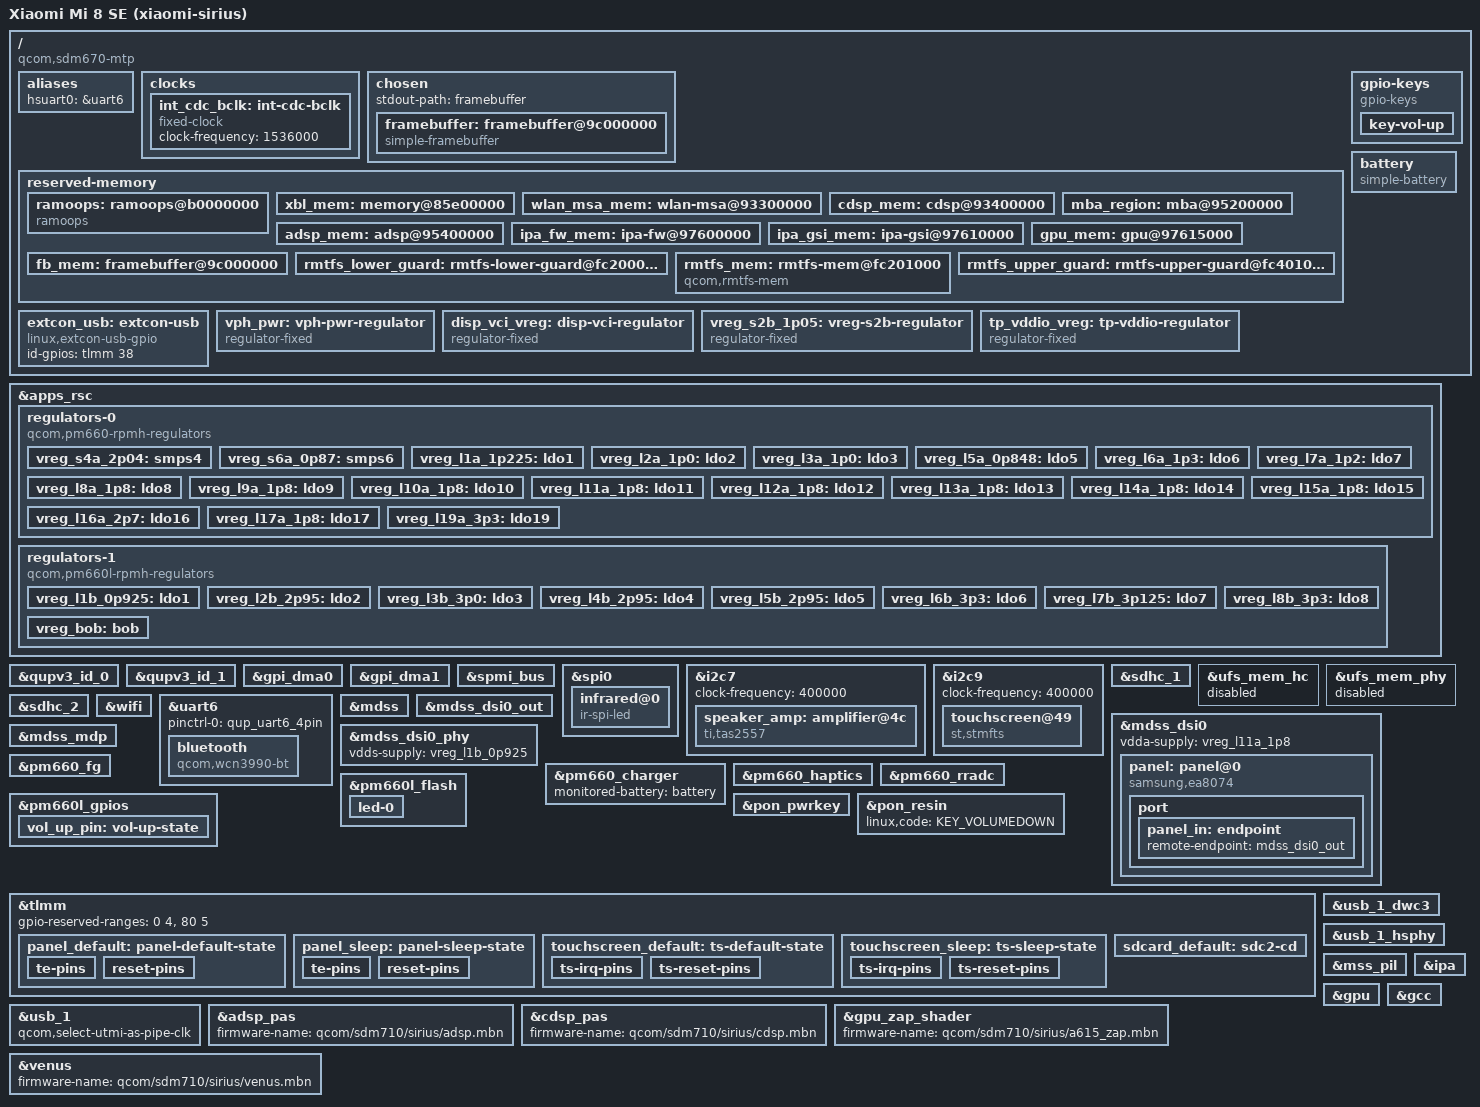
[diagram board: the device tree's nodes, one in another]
// SPDX-License-Identifier: GPL-2.0
/*
 * Device tree for Xiaomi Mi 8 SE (xiaomi-sirius).
 *
 * Derived from sdm710-xiaomi-pyxis.dts by Richard Acayan
 * (sdm670-mainline/linux). SoC-level pieces (sdm710.dtsi, UFS, SDHC,
 * PM660/PM660L regulators, WCN3990, fastrpc) are identical between
 * pyxis and sirius because both are SDM710.
 *
 * Device-specific values came from the downstream CAF kernel
 * (SDM710-Development/android_kernel_xiaomi_sdm710, 10.0-caf) and the
 * LineageOS device tree (SDM710-Development/android_device_xiaomi_sirius).
 *
 * Verify on your own unit before trusting:
 *   - qcom,msm-id  (read from the stock dtb; scripts/extract-stock-dtb.sh)
 *   - the panel compatible (sirius ships an EA8074-class AMOLED)
 *   - touchscreen IC (ST FTS here) and its reset GPIO
 */

/dts-v1/;
#include <dt-bindings/firmware/qcom,scm.h>
#include <dt-bindings/gpio/gpio.h>
#include <dt-bindings/input/input.h>
#include <dt-bindings/leds/common.h>
#include <dt-bindings/pinctrl/qcom,pmic-gpio.h>
#include <dt-bindings/power/qcom-rpmpd.h>
#include "sdm710.dtsi"
#include "pm660.dtsi"
#include "pm660l.dtsi"

/delete-node/ &xbl_mem;
/delete-node/ &wlan_msa_mem;
/delete-node/ &cdsp_mem;
/delete-node/ &mba_region;
/delete-node/ &adsp_mem;
/delete-node/ &ipa_fw_mem;
/delete-node/ &ipa_gsi_mem;
/delete-node/ &gpu_mem;
/delete-node/ &rmtfs_mem;

/ {
	model = "Xiaomi Mi 8 SE (xiaomi-sirius)";
	compatible = "qcom,sdm670-mtp", "qcom,sdm670", "qcom,mtp";
	qcom,msm-id = <0x168 0x0>;		/* on-device: /proc/device-tree/qcom,msm-id */
	qcom,board-id = <0x20 0>;		/* on-device: /proc/device-tree/qcom,board-id */
	chassis-type = "handset";

	aliases {
		hsuart0 = &uart6;
	};

	clocks {
		int_cdc_bclk: int-cdc-bclk {
			compatible = "fixed-clock";
			#clock-cells = <0>;
			clock-frequency = <1536000>;
		};
	};

	chosen {
		stdout-path = "framebuffer";
		#address-cells = <2>;
		#size-cells = <2>;
		ranges;

		/* 1080 x 2244 (NOT 2248). From downstream fts,y-max and
		 * LineageOS TARGET_SCREEN_HEIGHT.
		 */
		framebuffer: framebuffer@9c000000 {
			compatible = "simple-framebuffer";
			reg = <0 0x9c000000 0 (1080 * 2244 * 4)>;
			width = <1080>;
			height = <2244>;
			stride = <(1080 * 4)>;
			format = "a8r8g8b8";
			status = "okay";
		};
	};

	reserved-memory {
		#address-cells = <2>;
		#size-cells = <2>;

		/* keep the stock ramoops area so a dying mainline kernel still
		 * leaves its log behind, readable from TWRP at /sys/fs/pstore
		 */
		ramoops: ramoops@b0000000 {
			compatible = "ramoops";
			reg = <0 0xb0000000 0 0x400000>;
			console-size = <0x200000>;
			record-size = <0x40000>;
			ftrace-size = <0x40000>;
			pmsg-size = <0x20000>;
		};

		xbl_mem: memory@85e00000 {
			reg = <0 0x85e00000 0 0x1c0000>;
			no-map;
		};


		wlan_msa_mem: wlan-msa@93300000 {
			reg = <0 0x93300000 0 0x100000>;
			no-map;
		};

		cdsp_mem: cdsp@93400000 {
			reg = <0 0x93400000 0 0x1e00000>;
			no-map;
		};

		mba_region: mba@95200000 {
			reg = <0 0x95200000 0 0x200000>;
			no-map;
		};

		adsp_mem: adsp@95400000 {
			reg = <0 0x95400000 0 0x2200000>;
			no-map;
		};

		ipa_fw_mem: ipa-fw@97600000 {
			reg = <0 0x97600000 0 0x10000>;
			no-map;
		};

		ipa_gsi_mem: ipa-gsi@97610000 {
			reg = <0 0x97610000 0 0x5000>;
			no-map;
		};

		gpu_mem: gpu@97615000 {
			reg = <0 0x97615000 0 0x2000>;
			no-map;
		};

		fb_mem: framebuffer@9c000000 {
			reg = <0 0x9c000000 0 0x2300000>;
			no-map;
		};

		rmtfs_lower_guard: rmtfs-lower-guard@fc200000 {
			reg = <0 0xfc200000 0 0x1000>;
			no-map;
		};

		rmtfs_mem: rmtfs-mem@fc201000 {
			compatible = "qcom,rmtfs-mem";
			reg = <0 0xfc201000 0 0x200000>;
			no-map;
			qcom,client-id = <1>;
			qcom,vmid = <QCOM_SCM_VMID_MSS_MSA>;
		};

		rmtfs_upper_guard: rmtfs-upper-guard@fc401000 {
			reg = <0 0xfc401000 0 0x1000>;
			no-map;
		};
	};

	gpio-keys {
		compatible = "gpio-keys";
		autorepeat;

		pinctrl-names = "default";
		pinctrl-0 = <&vol_up_pin>;

		key-vol-up {
			label = "Volume Up";
			linux,code = <KEY_VOLUMEUP>;
			gpios = <&pm660l_gpios 7 GPIO_ACTIVE_LOW>;
		};
	};

	extcon_usb: extcon-usb {
		compatible = "linux,extcon-usb-gpio";
		id-gpios = <&tlmm 38 GPIO_ACTIVE_HIGH>;
	};

	battery: battery {
		compatible = "simple-battery";
		voltage-min-design-microvolt = <3312000>;
		voltage-max-design-microvolt = <4400000>;
	};

	vph_pwr: vph-pwr-regulator {
		compatible = "regulator-fixed";
		regulator-name = "vph_pwr";
		regulator-min-microvolt = <3312000>;
		regulator-max-microvolt = <3312000>;
		regulator-always-on;
		regulator-boot-on;
	};

	/*
	 * Panel VCI (3.0 V) enable. Verified against the vendor device tree of
	 * this unit (recovery FDT): the EA8074 3.0 V rail is
	 * /soc/disp_vci_vreg, a regulator-fixed on TLMM GPIO5 with
	 * enable-active-high and regulator-boot-on. GPIO76 - which the pyxis
	 * derived wiring used here - is qcom,panel-mode-gpio for the nt35597
	 * panels and is not bound anywhere on the EA8074 path, so it must not
	 * switch this rail.
	 *
	 * The vendor writes start-delay-us = <4000>. No C code reads that
	 * property (drivers/regulator/fixed.c reads startup-delay-us), so the
	 * delay never took effect downstream; the mainline property name below
	 * applies the 4 ms for the first time.
	 */
	disp_vci_vreg: disp-vci-regulator {
		compatible = "regulator-fixed";
		regulator-name = "disp_vci_vreg";
		regulator-min-microvolt = <3000000>;
		regulator-max-microvolt = <3000000>;
		gpios = <&tlmm 5 GPIO_ACTIVE_HIGH>;
		enable-active-high;
		startup-delay-us = <4000>;
		regulator-boot-on;
	};

	vreg_s2b_1p05: vreg-s2b-regulator {
		compatible = "regulator-fixed";
		regulator-name = "vreg_s2b";
		regulator-min-microvolt = <1050000>;
		regulator-max-microvolt = <1050000>;
	};

	/* sirius touch power: downstream tp_vddio_vreg on tlmm 26 */
	tp_vddio_vreg: tp-vddio-regulator {
		compatible = "regulator-fixed";
		regulator-name = "tp_vddio_vreg";
		startup-delay-us = <4000>;
		enable-active-high;
		regulator-boot-on;
		gpios = <&tlmm 26 GPIO_ACTIVE_HIGH>;
	};
};

/* --- PM660 / PM660L RPMh regulators (identical to pyxis) --- */
&apps_rsc {
	regulators-0 {
		compatible = "qcom,pm660-rpmh-regulators";
		qcom,pmic-id = "a";

		vdd-s1-supply = <&vph_pwr>;
		vdd-s2-supply = <&vph_pwr>;
		vdd-s3-supply = <&vph_pwr>;
		vdd-s4-supply = <&vph_pwr>;
		vdd-s5-supply = <&vph_pwr>;
		vdd-s6-supply = <&vph_pwr>;

		vdd-l1-l6-l7-supply = <&vreg_s6a_0p87>;
		vdd-l2-l3-supply = <&vreg_s2b_1p05>;
		vdd-l5-supply = <&vreg_s2b_1p05>;
		vdd-l8-l9-l10-l11-l12-l13-l14-supply = <&vreg_s4a_2p04>;
		vdd-l15-l16-l17-l18-l19-supply = <&vreg_bob>;

		vreg_s4a_2p04: smps4 {
			regulator-min-microvolt = <1808000>;
			regulator-max-microvolt = <2040000>;
			regulator-enable-ramp-delay = <200>;
		};

		vreg_s6a_0p87: smps6 {
			regulator-min-microvolt = <1224000>;
			regulator-max-microvolt = <1352000>;
			regulator-enable-ramp-delay = <150>;
		};

		vreg_l1a_1p225: ldo1 {
			regulator-min-microvolt = <1200000>;
			regulator-max-microvolt = <1250000>;
			regulator-enable-ramp-delay = <250>;
		};

		vreg_l2a_1p0: ldo2 {
			regulator-min-microvolt = <1000000>;
			regulator-max-microvolt = <1000000>;
			regulator-enable-ramp-delay = <250>;
		};

		vreg_l3a_1p0: ldo3 {
			regulator-min-microvolt = <1000000>;
			regulator-max-microvolt = <1000000>;
			regulator-enable-ramp-delay = <250>;
		};

		vreg_l5a_0p848: ldo5 {
			regulator-min-microvolt = <800000>;
			regulator-max-microvolt = <800000>;
			regulator-enable-ramp-delay = <250>;
		};

		vreg_l6a_1p3: ldo6 {
			regulator-min-microvolt = <1248000>;
			regulator-max-microvolt = <1304000>;
			regulator-enable-ramp-delay = <250>;
		};

		vreg_l7a_1p2: ldo7 {
			regulator-min-microvolt = <1200000>;
			regulator-max-microvolt = <1200000>;
			regulator-enable-ramp-delay = <250>;
		};

		vreg_l8a_1p8: ldo8 {
			regulator-min-microvolt = <1800000>;
			regulator-max-microvolt = <1800000>;
			regulator-enable-ramp-delay = <250>;
			regulator-always-on;
		};

		vreg_l9a_1p8: ldo9 {
			regulator-min-microvolt = <1800000>;
			regulator-max-microvolt = <1800000>;
			regulator-enable-ramp-delay = <250>;
		};

		vreg_l10a_1p8: ldo10 {
			regulator-min-microvolt = <1800000>;
			regulator-max-microvolt = <1800000>;
			regulator-enable-ramp-delay = <250>;
		};

		vreg_l11a_1p8: ldo11 {
			regulator-min-microvolt = <1800000>;
			regulator-max-microvolt = <1800000>;
			regulator-enable-ramp-delay = <250>;
		};

		vreg_l12a_1p8: ldo12 {
			regulator-min-microvolt = <1800000>;
			regulator-max-microvolt = <1800000>;
			regulator-enable-ramp-delay = <250>;
		};

		vreg_l13a_1p8: ldo13 {
			regulator-min-microvolt = <1800000>;
			regulator-max-microvolt = <1800000>;
			regulator-enable-ramp-delay = <250>;
		};

		vreg_l14a_1p8: ldo14 {
			regulator-min-microvolt = <1800000>;
			regulator-max-microvolt = <1800000>;
			regulator-enable-ramp-delay = <250>;
		};

		vreg_l15a_1p8: ldo15 {
			regulator-min-microvolt = <1800000>;
			regulator-max-microvolt = <2950000>;
			regulator-enable-ramp-delay = <250>;
		};

		vreg_l16a_2p7: ldo16 {
			regulator-min-microvolt = <2696000>;
			regulator-max-microvolt = <2696000>;
			regulator-enable-ramp-delay = <250>;
		};

		vreg_l17a_1p8: ldo17 {
			regulator-min-microvolt = <1800000>;
			regulator-max-microvolt = <2950000>;
			regulator-enable-ramp-delay = <250>;
		};

		vreg_l19a_3p3: ldo19 {
			regulator-min-microvolt = <3000000>;
			regulator-max-microvolt = <3312000>;
			regulator-enable-ramp-delay = <250>;
		};
	};

	regulators-1 {
		compatible = "qcom,pm660l-rpmh-regulators";
		qcom,pmic-id = "b";

		vdd-s1-supply = <&vph_pwr>;
		vdd-s2-supply = <&vph_pwr>;
		vdd-s3-s4-supply = <&vph_pwr>;
		vdd-s5-supply = <&vph_pwr>;

		vdd-l1-l9-l10-supply = <&vreg_s2b_1p05>;
		vdd-l2-supply = <&vreg_bob>;
		vdd-l3-l5-l7-l8-supply = <&vreg_bob>;
		vdd-l4-l6-supply = <&vreg_bob>;
		vdd-bob-supply = <&vph_pwr>;

		vreg_l1b_0p925: ldo1 {
			regulator-min-microvolt = <880000>;
			regulator-max-microvolt = <900000>;
			regulator-enable-ramp-delay = <250>;
		};

		vreg_l2b_2p95: ldo2 {
			regulator-min-microvolt = <1800000>;
			regulator-max-microvolt = <2960000>;
			regulator-enable-ramp-delay = <250>;
		};

		vreg_l3b_3p0: ldo3 {
			regulator-min-microvolt = <2800000>;
			regulator-max-microvolt = <3008000>;
			regulator-enable-ramp-delay = <250>;
		};

		vreg_l4b_2p95: ldo4 {
			regulator-min-microvolt = <2960000>;
			regulator-max-microvolt = <2960000>;
			regulator-enable-ramp-delay = <250>;
		};

		vreg_l5b_2p95: ldo5 {
			regulator-min-microvolt = <2960000>;
			regulator-max-microvolt = <2960000>;
			regulator-enable-ramp-delay = <250>;
		};

		vreg_l6b_3p3: ldo6 {
			regulator-min-microvolt = <3008000>;
			regulator-max-microvolt = <3300000>;
			regulator-enable-ramp-delay = <250>;
		};

		vreg_l7b_3p125: ldo7 {
			regulator-min-microvolt = <3088000>;
			regulator-max-microvolt = <3100000>;
			regulator-enable-ramp-delay = <250>;
		};

		vreg_l8b_3p3: ldo8 {
			regulator-min-microvolt = <3300000>;
			regulator-max-microvolt = <3312000>;
			regulator-enable-ramp-delay = <250>;
		};

		vreg_bob: bob {
			regulator-min-microvolt = <3296000>;
			regulator-max-microvolt = <3328000>;
			regulator-enable-ramp-delay = <500>;
		};
	};
};

/* --- Buses --- */
&qupv3_id_0 { status = "okay"; };
&qupv3_id_1 { status = "okay"; };
&gpi_dma0 { status = "okay"; };
&gpi_dma1 { status = "okay"; };
&spmi_bus { status = "okay"; };

/* IR blaster (downstream: qupv3_se0_spi, ir-spi @0) */
&spi0 {
	status = "okay";

	infrared@0 {
		compatible = "ir-spi-led";
		reg = <0x00>;
		spi-max-frequency = <19200000>;
	};
};

/* Audio amp: TI TAS2557 on i2c7 (downstream qupv3_se7_i2c) */
&i2c7 {
	status = "okay";
	clock-frequency = <400000>;

	speaker_amp: amplifier@4c {
		compatible = "ti,tas2557";
		reg = <0x4c>;
		#sound-dai-cells = <0>;
		reset-gpios = <&tlmm 95 GPIO_ACTIVE_HIGH>;
		interrupts-extended = <&tlmm 96 IRQ_TYPE_EDGE_FALLING>;
	};
};

/* Touchscreen: ST FTS on i2c9 (downstream qupv3_se9_i2c).
 * sirius reset GPIO 99, IRQ 125.
 */
&i2c9 {
	status = "okay";
	clock-frequency = <400000>;

	touchscreen@49 {
		compatible = "st,stmfts";
		reg = <0x49>;

		interrupts-extended = <&tlmm 125 IRQ_TYPE_EDGE_FALLING>;
		reset-gpios = <&tlmm 99 GPIO_ACTIVE_LOW>;

		pinctrl-names = "default", "sleep";
		pinctrl-0 = <&touchscreen_default>;
		pinctrl-1 = <&touchscreen_sleep>;

		vdd-supply = <&tp_vddio_vreg>;
		avdd-supply = <&vreg_l6b_3p3>;

		touchscreen-size-x = <1080>;
		touchscreen-size-y = <2244>;
	};
};

/* --- Storage --- */
/*
 * Storage: eMMC on sdhc_1.
 *
 * The bootloader reports androidboot.bootdevice=7c4000.sdhci, i.e. sirius
 * boots from the eMMC controller at 0x7c4000, and the Mi 8 SE ships eMMC
 * rather than UFS. sdm710.dtsi (via sdm670.dtsi) leaves sdhc_1 disabled, so
 * this board never got a block device at all. Rails and timing follow the
 * working sdm670 reference (sdm670-google-common.dtsi).
 */
&sdhc_1 {
	status = "okay";

	supports-cqe;
	mmc-hs200-1_8v;
	mmc-hs400-1_8v;
	mmc-ddr-1_8v;

	qcom,ddr-config = <0xc3040873>;

	vmmc-supply = <&vreg_l4b_2p95>;
	vqmmc-supply = <&vreg_l8a_1p8>;
};

/*
 * There is no UFS on this board, and leaving it enabled only makes it fight
 * the eMMC for vreg_l4b_2p95 (the eMMC vmmc above) while failing to link up.
 */
&ufs_mem_hc {
	status = "disabled";
};

&ufs_mem_phy {
	status = "disabled";
};

&sdhc_2 {
	status = "okay";
	vmmc-supply = <&vreg_l5b_2p95>;
	vqmmc-supply = <&vreg_l2b_2p95>;
	cd-gpios = <&tlmm 126 GPIO_ACTIVE_HIGH>;
	pinctrl-0 = <&sdcard_default>;
	pinctrl-names = "default";
	no-sdio;
	no-mmc;
};

/* --- WiFi / Bluetooth (WCN3990) --- */
&wifi {
	status = "okay";

	vdd-0.8-cx-mx-supply = <&vreg_l5a_0p848>;
	vdd-1.8-xo-supply = <&vreg_l9a_1p8>;
	vdd-1.3-rfa-supply = <&vreg_l6a_1p3>;
	vdd-3.3-ch0-supply = <&vreg_l19a_3p3>;

	qcom,snoc-host-cap-8bit-quirk;
};

&uart6 {
	pinctrl-0 = <&qup_uart6_4pin>;
	status = "okay";

	bluetooth {
		compatible = "qcom,wcn3990-bt";
		vddio-supply = <&vph_pwr>;
		vddxo-supply = <&vreg_l9a_1p8>;
		vddrf-supply = <&vreg_l6a_1p3>;
		vddch0-supply = <&vreg_l19a_3p3>;
		max-speed = <3200000>;
	};
};

/* --- Display --- */
&mdss { status = "okay"; };

&mdss_dsi0 {
	status = "okay";
	vdda-supply = <&vreg_l11a_1p8>;

	panel: panel@0 {
		status = "okay";
		/* Confirmed on device: cmdline msm_drm.dsi_display0=dsi_ss_ea8074_fhd_cmd_display:config2
		 * VERIFY against downstream dsi_ss_fhd_ea8074_cmd / panel DT.
		 */
		compatible = "samsung,ea8074";
		reg = <0>;

		/* TE reaches the DPU through the pinmux below (gpio10 ->
		 * mdp_vsync), which the command-mode INTF tearcheck reads
		 * (dpu_encoder_phys_cmd_tearcheck_config()). No panel, msm DSI
		 * host or panel driver consumes a "te-gpios" descriptor -- verified
		 * against the pinned sources (drm_panel.c, the msm DSI host/manager
		 * and the panel drivers all return no hit) -- so it is deliberately
		 * not declared here. The binding sets additionalProperties: false,
		 * and a property no driver reads is schema noise rather than
		 * documentation. Live state on hardware: gpio10 reads func1
		 * (mdp_vsync) and gpio75 out high (reset released).
		 */
		/* Physical reset waveform from the vendor array: LOW 2 ms, then
		 * HIGH 11 ms. With GPIO_ACTIVE_LOW the driver drives logical 1
		 * (= physical LOW) for 2 ms and logical 0 (= physical HIGH) for
		 * 11 ms.
		 */
		reset-gpios = <&tlmm 75 GPIO_ACTIVE_LOW>;

		pinctrl-names = "default", "sleep";
		pinctrl-0 = <&panel_default>;
		pinctrl-1 = <&panel_sleep>;

		/* The vendor panel-supply-entries list exactly two rails for this
		 * panel: vddio 1.8 V (PM660 L11) and vci 3.0 V. There is no 3.3 V
		 * rail, so the pyxis derived vdd3p3-supply is gone; the lab/ibb
		 * phandles the vendor display node also carries are not required
		 * supplies and are deliberately not wired up.
		 */
		vddio-supply = <&vreg_l11a_1p8>;
		vci-supply = <&disp_vci_vreg>;

		port {
			panel_in: endpoint {
				remote-endpoint = <&mdss_dsi0_out>;
			};
		};
	};
};

&mdss_dsi0_out {
	data-lanes = <0 1 2 3>;
	remote-endpoint = <&panel_in>;
};

&mdss_dsi0_phy {
	status = "okay";
	vdds-supply = <&vreg_l1b_0p925>;
};

&mdss_mdp { status = "okay"; };

/* --- PMIC blocks --- */
&pm660_charger {
	monitored-battery = <&battery>;
	status = "okay";
};

&pm660_fg {
	monitored-battery = <&battery>;
	power-supplies = <&pm660_charger>;
	status = "okay";
};

&pm660_haptics { status = "okay"; };
&pm660_rradc { status = "okay"; };

&pm660l_flash {
	status = "okay";

	led-0 {
		function = LED_FUNCTION_FLASH;
		color = <LED_COLOR_ID_WHITE>;
		led-sources = <1>, <2>;
		led-max-microamp = <350000>;
		flash-max-microamp = <1000000>;
		flash-max-timeout-us = <1280000>;
	};
};

&pm660l_gpios {
	vol_up_pin: vol-up-state {
		pins = "gpio7";
		function = "normal";
		qcom,drive-strength = <PMIC_GPIO_STRENGTH_NO>;
		input-enable;
		bias-pull-up;
	};
};

&pon_pwrkey { status = "okay"; };

&pon_resin {
	linux,code = <KEY_VOLUMEDOWN>;
	status = "okay";
};

/* --- SoC GPIO / pinctrl --- */
&tlmm {
	gpio-reserved-ranges = <0 4>, <80 5>;

	panel_default: panel-default-state {
		te-pins {
			pins = "gpio10";
			function = "mdp_vsync";
			drive-strength = <2>;
			bias-pull-down;
		};

		reset-pins {
			pins = "gpio75";
			function = "gpio";
			drive-strength = <8>;
			bias-disable;
		};
	};

	panel_sleep: panel-sleep-state {
		te-pins {
			pins = "gpio10";
			function = "mdp_vsync";
			drive-strength = <2>;
			bias-pull-down;
		};

		reset-pins {
			pins = "gpio75";
			function = "gpio";
			drive-strength = <8>;
			bias-disable;
		};
	};

	touchscreen_default: ts-default-state {
		ts-irq-pins {
			pins = "gpio125";
			function = "gpio";
			drive-strength = <10>;
			bias-pull-up;
		};

		ts-reset-pins {
			pins = "gpio99";
			function = "gpio";
			drive-strength = <10>;
			bias-pull-up;
		};
	};

	touchscreen_sleep: ts-sleep-state {
		ts-irq-pins {
			pins = "gpio125";
			function = "gpio";
			drive-strength = <10>;
			bias-disable;
		};

		ts-reset-pins {
			pins = "gpio99";
			function = "gpio";
			drive-strength = <10>;
			bias-disable;
		};
	};

	sdcard_default: sdc2-cd {
		pins = "gpio126";
		function = "gpio";
		drive-strength = <2>;
		bias-pull-up;
	};
};

/* --- USB (USB2.0 only, like pyxis) --- */
&usb_1 {
	status = "okay";
	qcom,select-utmi-as-pipe-clk;
};

&usb_1_dwc3 {
	dr_mode = "peripheral";
	extcon = <&extcon_usb>;
	phys = <&usb_1_hsphy>;
	phy-names = "usb2-phy";
	maximum-speed = "high-speed";
	/delete-property/ snps,dis_u2_susphy_quirk;
	/delete-property/ snps,dis_enblslpm_quirk;
};

&usb_1_hsphy {
	status = "okay";
	vdd-supply = <&vreg_l1b_0p925>;
	vdda-pll-supply = <&vreg_l10a_1p8>;
	vdda-phy-dpdm-supply = <&vreg_l7b_3p125>;
};

/* --- Remoteproc / firmware (qcom/sdm710/sirius/) --- */
&adsp_pas {
	status = "okay";
	firmware-name = "qcom/sdm710/sirius/adsp.mbn";
};

&cdsp_pas {
	status = "okay";
	firmware-name = "qcom/sdm710/sirius/cdsp.mbn";
};

&mss_pil {
	status = "okay";
	firmware-name = "qcom/sdm710/sirius/mba.mbn",
			"qcom/sdm710/sirius/modem.mbn";
};

&ipa {
	status = "okay";
	qcom,gsi-loader = "self";
	memory-region = <&ipa_fw_mem>;
	firmware-name = "qcom/sdm710/sirius/ipa_fws.mbn";
};

&gpu { status = "okay"; };

&gpu_zap_shader {
	firmware-name = "qcom/sdm710/sirius/a615_zap.mbn";
};

&venus {
	status = "okay";
	firmware-name = "qcom/sdm710/sirius/venus.mbn";
};

&gcc {
	protected-clocks = <GCC_QSPI_CORE_CLK>,
		<GCC_QSPI_CORE_CLK_SRC>,
		<GCC_QSPI_CNOC_PERIPH_AHB_CLK>;
};
